VERSION ""

NS_ :

BS_: 500

BU_: Vector__XXX

BO_ 24 MSG_018: 8 Vector__XXX
 SG_ Steering_Angle : 48|16@0- (-0.1,0) [-720|720] "��" Vector__XXX

BO_ 209 MSG_0D1: 4 Vector__XXX
 SG_ Brake_Position : 40|8@0+ (1,0) [0|255] "" Vector__XXX

BO_ 211 MSG_0D3: 7 Vector__XXX
 SG_ Traction_Control_Mode : 61|1@0+ (1,0) [0|1] "on/off" Vector__XXX

BO_ 212 MSG_0D4: 8 Vector__XXX
 SG_ Wheel_Speed_FL_kph : 0|16@1+ (0.058,0) [0|65535] "km/h" Vector__XXX
 SG_ Wheel_Speed_FL_mph : 0|16@1+ (0.036018,0) [0|40697.235] "mph" Vector__XXX
 SG_ Wheel_Speed_FR_kph : 16|16@1+ (0.058,0) [0|65535] "km/h" Vector__XXX
 SG_ Wheel_Speed_FR_mph : 16|16@1+ (0.036018,0) [0|40697.235] "mph" Vector__XXX
 SG_ Wheel_Speed_RL_kph : 32|16@1+ (0.058,0) [0|65535] "km/h" Vector__XXX
 SG_ Wheel_Speed_RL_mph : 32|16@1+ (0.036018,0) [0|40697.235] "mph" Vector__XXX
 SG_ Wheel_Speed_RR_kph : 48|16@1+ (0.058,0) [0|65535] "km/h" Vector__XXX
 SG_ Wheel_Speed_RR_mph : 48|16@1+ (0.036018,0) [0|40697.235] "mph" Vector__XXX

BO_ 320 MSG_140: 8 Vector__XXX
 SG_ Engine_Speed : 16|14@1+ (1,0) [0|10000] "rpm" Vector__XXX
 SG_ Clutch_Position : 55|1@0+ (1,0) [0|1] "on/off" Vector__XXX
 SG_ Accelerator_Pedal_Position : 56|8@0+ (0.392157,0) [0|100] "%" Vector__XXX

BO_ 321 MSG_141: 8 Vector__XXX
 SG_ Gear : 48|4@1+ (1,0) [0|128] "" Vector__XXX

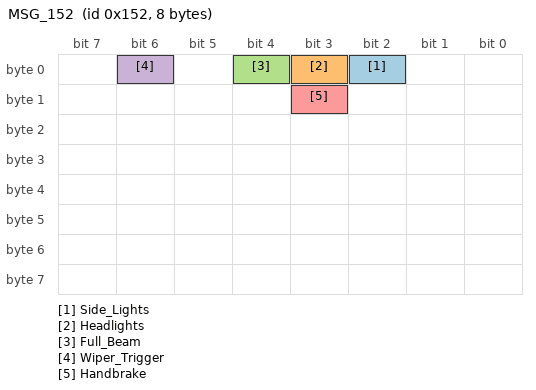
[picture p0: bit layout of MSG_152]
BO_ 338 MSG_152: 8 Vector__XXX
 SG_ Side_Lights : 2|1@0+ (1,0) [0|0] "on/off" Vector__XXX
 SG_ Headlights : 3|1@0+ (1,0) [0|0] "on/off" Vector__XXX
 SG_ Full_Beam : 4|1@0+ (1,0) [0|0] "on/off" Vector__XXX
 SG_ Wiper_Trigger : 6|1@0+ (1,0) [0|0] "on/off" Vector__XXX
 SG_ Handbrake : 11|1@0+ (1,0) [0|0] "on/off" Vector__XXX

BO_ 642 MSG_282: 8 Vector__XXX
 SG_ Seat_Belt___Driver : 16|1@0+ (1,0) [0|1] "on/off" Vector__XXX

BO_ 864 MSG_360: 8 Vector__XXX
 SG_ Oil_Temperature : 16|8@1+ (1,-40) [0|160] "��C" Vector__XXX
 SG_ Coolant_Temperature : 24|8@1+ (1,-40) [0|120] "��C" Vector__XXX
